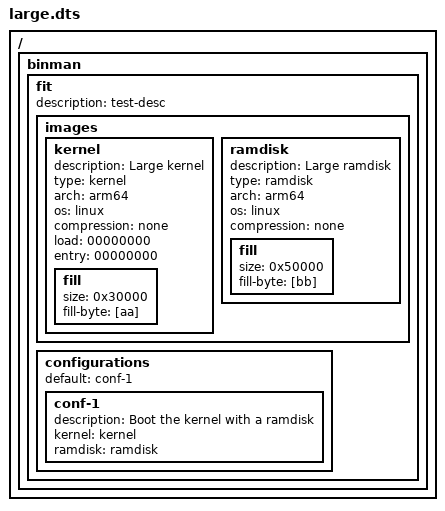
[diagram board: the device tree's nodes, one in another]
// SPDX-License-Identifier: GPL-2.0+

/dts-v1/;

/ {
	#address-cells = <1>;
	#size-cells = <1>;

	binman {
		fit {
			description = "test-desc";
			#address-cells = <1>;

			images {
				kernel {
					description = "Large kernel";
					type = "kernel";
					arch = "arm64";
					os = "linux";
					compression = "none";
					load = <00000000>;
					entry = <00000000>;
					fill {
						size = <0x30000>;
						fill-byte = [aa];
					};
				};
				ramdisk {
					description = "Large ramdisk";
					type = "ramdisk";
					arch = "arm64";
					os = "linux";
					compression = "none";
					fill {
						size = <0x50000>;
						fill-byte = [bb];
					};
				};
			};

			configurations {
				default = "conf-1";
				conf-1 {
					description = "Boot the kernel with a ramdisk";
					kernel = "kernel";
					ramdisk = "ramdisk";
				};
			};
		};
	};
};
